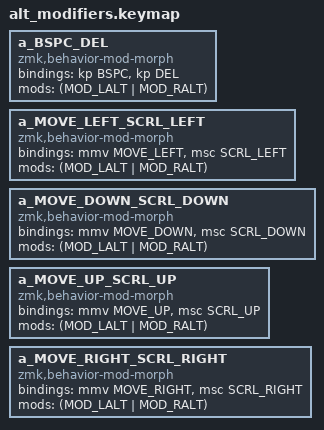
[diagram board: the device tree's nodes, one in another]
/* 
    keyoutput[default]  ¦  keyoutput[with modifer]
    a[for alt]_key[default]_key[in combination with modifer]: a[for alt]_key[default]_key[in combination with modifer]
*/

/* BSPC  ¦  DEL */
a_BSPC_DEL: a_BSPC_DEL {
    compatible = "zmk,behavior-mod-morph";
    #binding-cells = <0>;
    bindings = <&kp BSPC>, <&kp DEL>;
    mods = <(MOD_LALT | MOD_RALT)>;
};
/* MOVE_LEFT  ¦  SCROLL LEFT */
a_MOVE_LEFT_SCRL_LEFT: a_MOVE_LEFT_SCRL_LEFT {
    compatible = "zmk,behavior-mod-morph";
    #binding-cells = <0>;
    bindings = <&mmv MOVE_LEFT>, <&msc SCRL_LEFT>;
    mods = <(MOD_LALT | MOD_RALT)>;
};
/* MOVE_DOWN  ¦  SCROLL DOWN */
a_MOVE_DOWN_SCRL_DOWN: a_MOVE_DOWN_SCRL_DOWN {
    compatible = "zmk,behavior-mod-morph";
    #binding-cells = <0>;
    bindings = <&mmv MOVE_DOWN>, <&msc SCRL_DOWN>;
    mods = <(MOD_LALT | MOD_RALT)>;
};
/* MOVE_UP  ¦  SCROLL UP */
a_MOVE_UP_SCRL_UP: a_MOVE_UP_SCRL_UP {
    compatible = "zmk,behavior-mod-morph";
    #binding-cells = <0>;
    bindings = <&mmv MOVE_UP>, <&msc SCRL_UP>;
    mods = <(MOD_LALT | MOD_RALT)>;
};
/* MOVE_RIGHT  ¦  SCROLL RIGHT */
a_MOVE_RIGHT_SCRL_RIGHT: a_MOVE_RIGHT_SCRL_RIGHT {
    compatible = "zmk,behavior-mod-morph";
    #binding-cells = <0>;
    bindings = <&mmv MOVE_RIGHT>, <&msc SCRL_RIGHT>;
    mods = <(MOD_LALT | MOD_RALT)>;
};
